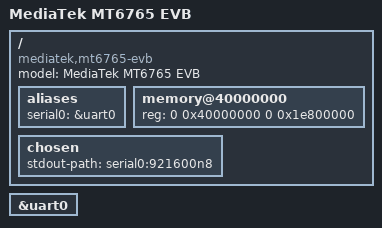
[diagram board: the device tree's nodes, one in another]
// SPDX-License-Identifier: GPL-2.0
/*
 * dts file for Mediatek MT6765
 *
 * (C) Copyright 2018. Mediatek, Inc.
 *
 * Mars Cheng <mars.cheng@mediatek.com>
 */

/dts-v1/;
#include "mt6765.dtsi"

/ {
	model = "MediaTek MT6765 EVB";
	compatible = "mediatek,mt6765-evb", "mediatek,mt6765";

	aliases {
		serial0 = &uart0;
	};

	memory@40000000 {
		device_type = "memory";
		reg = <0 0x40000000 0 0x1e800000>;
	};

	chosen {
		stdout-path = "serial0:921600n8";
	};
};

&uart0 {
	status = "okay";
};
